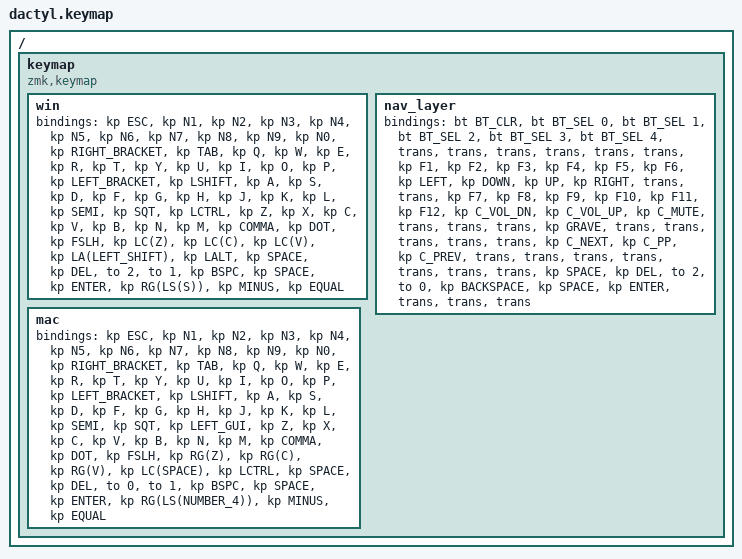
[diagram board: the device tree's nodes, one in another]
#include <behaviors.dtsi>
#include <dt-bindings/zmk/bt.h>
#include <dt-bindings/zmk/keys.h>

#define BASE 0
#define SYM  1
#define NAV  2

/ {
    keymap {
        compatible = "zmk,keymap";

        /*
         * Thumb clusters read outer -> inner on the left and inner -> outer on
         * the right, so the two innermost keys (space and enter) sit next to
         * each other in the middle. Hold space for SYM, hold enter for NAV —
         * each layer is driven by the thumb of the hand not typing on it.
         */

        win {
            bindings = <
&kp ESC  &kp N1  &kp N2  &kp N3  &kp N4  &kp N5  &kp N6  &kp N7  &kp N8  &kp N9  &kp N0  &kp RIGHT_BRACKET  &kp TAB  &kp Q  &kp W  &kp E  &kp R  &kp T  &kp Y  &kp U  &kp I  &kp O  &kp P  &kp LEFT_BRACKET  &kp LSHIFT  &kp A  &kp S  &kp D  &kp F  &kp G  &kp H  &kp J  &kp K  &kp L  &kp SEMI  &kp SQT  &kp LCTRL  &kp Z  &kp X  &kp C  &kp V  &kp B  &kp N  &kp M  &kp COMMA  &kp DOT  &kp FSLH  &kp LC(Z)  &kp LC(C)  &kp LC(V)  &kp LA(LEFT_SHIFT)  &kp LALT  &kp SPACE  &kp DEL  &to 2  &to 1  &kp BSPC  &kp SPACE  &kp ENTER  &kp RG(LS(S))  &kp MINUS  &kp EQUAL
            >;
        };

        nav_layer {
            bindings = <
&bt BT_CLR  &bt BT_SEL 0  &bt BT_SEL 1  &bt BT_SEL 2  &bt BT_SEL 3  &bt BT_SEL 4  &trans  &trans  &trans  &trans  &trans  &trans  &kp F1  &kp F2  &kp F3  &kp F4  &kp F5  &kp F6  &kp LEFT  &kp DOWN  &kp UP  &kp RIGHT  &trans  &trans  &kp F7  &kp F8  &kp F9  &kp F10  &kp F11  &kp F12  &kp C_VOL_DN  &kp C_VOL_UP  &kp C_MUTE  &trans  &trans  &trans  &kp GRAVE  &trans  &trans  &trans  &trans  &trans  &kp C_NEXT  &kp C_PP  &kp C_PREV  &trans  &trans  &trans  &trans  &trans  &trans  &trans  &kp SPACE  &kp DEL  &to 2  &to 0  &kp BACKSPACE  &kp SPACE  &kp ENTER  &trans  &trans  &trans
            >;
        };

        mac {
            bindings = <
&kp ESC  &kp N1  &kp N2  &kp N3  &kp N4  &kp N5  &kp N6  &kp N7  &kp N8  &kp N9  &kp N0  &kp RIGHT_BRACKET  &kp TAB  &kp Q  &kp W  &kp E  &kp R  &kp T  &kp Y  &kp U  &kp I  &kp O  &kp P  &kp LEFT_BRACKET  &kp LSHIFT  &kp A  &kp S  &kp D  &kp F  &kp G  &kp H  &kp J  &kp K  &kp L  &kp SEMI  &kp SQT  &kp LEFT_GUI  &kp Z  &kp X  &kp C  &kp V  &kp B  &kp N  &kp M  &kp COMMA  &kp DOT  &kp FSLH  &kp RG(Z)  &kp RG(C)  &kp RG(V)  &kp LC(SPACE)  &kp LCTRL  &kp SPACE  &kp DEL  &to 0  &to 1  &kp BSPC  &kp SPACE  &kp ENTER  &kp RG(LS(NUMBER_4))  &kp MINUS  &kp EQUAL
            >;
        };
    };
};
